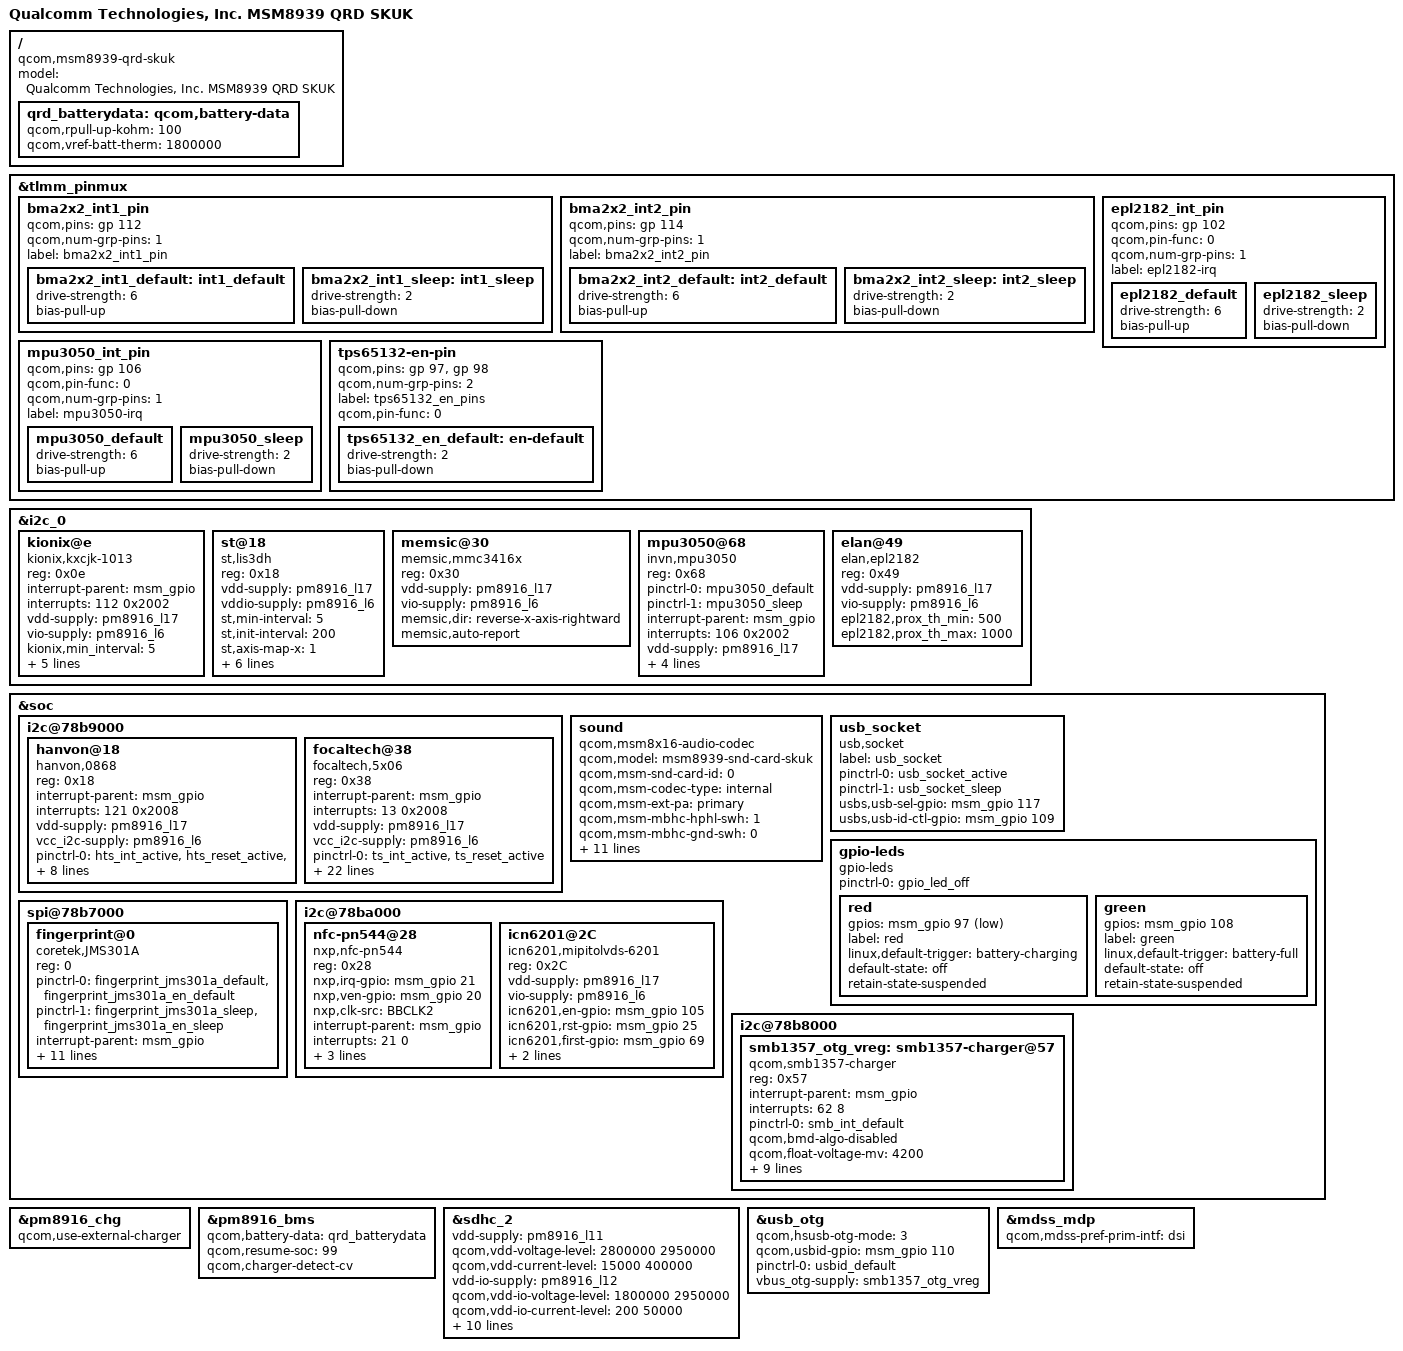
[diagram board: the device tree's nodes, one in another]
/* Copyright (c) 2014, The Linux Foundation. All rights reserved.
 *
 * This program is free software; you can redistribute it and/or modify
 * it under the terms of the GNU General Public License version 2 and
 * only version 2 as published by the Free Software Foundation.
 *
 * This program is distributed in the hope that it will be useful,
 * but WITHOUT ANY WARRANTY; without even the implied warranty of
 * MERCHANTABILITY or FITNESS FOR A PARTICULAR PURPOSE.  See the
 * GNU General Public License for more details.
 */

#include "msm8939-qrd.dtsi"
//#include "dsi-panel-nt35596-1080p-skuk-video.dtsi"
//#include "dsi-panel-nt51021-1200p-skuk-video.dtsi"		// lee add, 20141224
#include "msm8939-camera-sensor-qrd.dtsi"
#include "msm8916-mdss-panels.dtsi"
/ {
	model = "Qualcomm Technologies, Inc. MSM8939 QRD SKUK";
	compatible = "qcom,msm8939-qrd-skuk", "qcom,msm8939-qrd", "qcom,msm8939", "qcom,qrd";
};

&tlmm_pinmux {
	bma2x2_int1_pin {
		qcom,pins = <&gp 112>;
		qcom,num-grp-pins = <1>;
		label = "bma2x2_int1_pin";
		bma2x2_int1_default: int1_default {
			  drive-strength = <6>;
			  bias-pull-up;
		};
		bma2x2_int1_sleep: int1_sleep {
			  drive-strength = <2>;
			  bias-pull-down;
		};
	};

	bma2x2_int2_pin {
		qcom,pins = <&gp 114>;
		qcom,num-grp-pins = <1>;
		label = "bma2x2_int2_pin";
		bma2x2_int2_default: int2_default {
			  drive-strength = <6>;
			  bias-pull-up;
		};
		bma2x2_int2_sleep: int2_sleep {
			  drive-strength = <2>;
			  bias-pull-down;
		};
	};

	epl2182_int_pin {
		qcom,pins = <&gp 102>;
		qcom,pin-func = <0>;
		qcom,num-grp-pins = <1>;
		label = "epl2182-irq";
		epl2182_default: epl2182_default {
			drive-strength = <6>;
			bias-pull-up;
		};
		epl2182_sleep: epl2182_sleep {
			drive-strength = <2>;
			bias-pull-down;
		};
	};

	mpu3050_int_pin {
		qcom,pins = <&gp 106>;
		qcom,pin-func = <0>;
		qcom,num-grp-pins = <1>;
		label = "mpu3050-irq";
		mpu3050_default: mpu3050_default {
			drive-strength = <6>;
			bias-pull-up;
		};
		mpu3050_sleep: mpu3050_sleep {
			drive-strength = <2>;
			bias-pull-down;
		};
	};
	
/*	hall_int_pin {
		qcom,pins = <&gp 121>;
		qcom,pin-func = <0>;
		qcom,num-grp-pins = <1>;
		label = "hall-irq";
		hall_default: hall_default {
			drive-strength = <6>;
			bias-disable;
		};
		hall_sleep: hall_sleep {
			drive-strength = <2>;
			bias-disable;
		};
	};*/
	
	tps65132-en-pin {
		qcom,pins = <&gp 97>, <&gp 98>;
		qcom,num-grp-pins = <2>;
		label = "tps65132_en_pins";
		qcom,pin-func = <0>;

		tps65132_en_default: en-default {
			drive-strength = <2>;
			bias-pull-down;
		};
	};
};

&i2c_0 { /* BLSP1 QUP2 */
/*	avago@96 { // Ambient light and proximity sensor
		compatible = "avago,apds9930";
		reg = <0x96>;
		pinctrl-names = "default","sleep";
		pinctrl-0 = <&apds99xx_default>;
		pinctrl-1 = <&apds99xx_sleep>;
		interrupt-parent = <&msm_gpio>;
		interrupts = <113 0x2002>;
		vdd-supply = <&pm8916_l17>;
		vio-supply = <&pm8916_l6>;
		avago,irq-gpio = <&msm_gpio 113 0x2002>;
		avago,ps-threshold = <600>;
		avago,ps-hysteresis-threshold = <500>;
		avago,ps-pulse = <8>;
		avago,ps-pgain = <0>;
		avago,als-B = <186>;
		avago,als-C = <75>;
		avago,als-D = <129>;
		avago,ga-value = <560>;
	};
*/
/*
	bosch@18 { // Accelerometer sensor
		compatible = "bosch,bma2x2";
		reg = <0x18>;
		pinctrl-names = "bma_default","bma_sleep";
		pinctrl-0 = <&bma2x2_int1_default &bma2x2_int2_default>;
		pinctrl-1 = <&bma2x2_int1_sleep &bma2x2_int2_sleep>;
		interrupt-parent = <&msm_gpio>;
		interrupts = <112 0x2002>;
		vdd-supply = <&pm8916_l17>;
		vio-supply = <&pm8916_l6>;
		bosch,init-interval = <200>;
		bosch,place = <2>;
		bosch,gpio-int1 = <&msm_gpio 112 0x2002>;
		bosch,gpio-int2 = <&msm_gpio 114 0x2002>;
	};
*/
	// lee add, 20150105, for G-sensor.
	kionix@e { /* Accelerometer sensor */
		compatible = "kionix,kxcjk-1013";
		reg = <0x0e>;
		interrupt-parent = <&msm_gpio>;
		interrupts = <112 0x2002>;
		vdd-supply = <&pm8916_l17>;
		vio-supply = <&pm8916_l6>;
		kionix,min_interval = <5>;
		kionix,poll_interval = <100>;
		kionix,accel_direction = <8>;
		kionix,accel_irq_use_drdy = <0>;
		kionix,accel_res = <12>;
		kionix,accel_g_range = <2>;
	};
	// lee add, 20150130, for G-sensor.
	st@18 {
		compatible = "st,lis3dh";
		reg = <0x18>;
		vdd-supply = <&pm8916_l17>;
		vddio-supply = <&pm8916_l6>;
		st,min-interval = <5>;
		st,init-interval = <200>;
		st,axis-map-x = <1>;
		st,axis-map-y = <0>;
		st,axis-map-z = <2>;
		st,g-range = <2>;
		st,gpio-int1 = <&msm_gpio 112 0x2002>;
		st,negate-x;
//		st,negate-y;
		st,negate-z;
	};

	memsic@30 { /* Magnetic field sensor */
		compatible = "memsic,mmc3416x";
		reg = <0x30>;
		vdd-supply = <&pm8916_l17>;
		vio-supply = <&pm8916_l6>;
		memsic,dir = "reverse-x-axis-rightward";
//		memsic,dir = "obverse-x-axis-leftward";
		memsic,auto-report;
	};

	// lee add, 20150105, for Gyroscope sensor.
	mpu3050@68 {
		#address-cells = <1>;
		#size-cells = <0>;
		status = "okay";
		reg = <0x68>;
		compatible = "invn,mpu3050";
		pinctrl-names = "default","sleep";
		pinctrl-0 = <&mpu3050_default>;
		pinctrl-1 = <&mpu3050_sleep>;
		interrupt-parent = <&msm_gpio>;
		interrupts = <106 0x2002>;
		vdd-supply = <&pm8916_l17>;
		vlogic-supply = <&pm8916_l6>;
		invn,gpio-int = <&msm_gpio 106 0x2002>;
		invn,gpio-en = <&pm8916_gpios 3 0x2>;
		invn,poll-interval = <200>;
	};
	
	// lee add, 20150105, for Ambient light and proximity sensor.
	elan@49 { // Ambient light and proximity sensor
		compatible = "elan,epl2182";
		reg = <0x49>;
//		pinctrl-names = "default","sleep";
//		pinctrl-0 = <&epl2182_default>;
//		pinctrl-1 = <&epl2182_sleep>;
//		interrupt-parent = <&msm_gpio>;
//		interrupts = <113 0x2002>;
		vdd-supply = <&pm8916_l17>;
		vio-supply = <&pm8916_l6>;
//		epl2182,irq-gpio = <&msm_gpio 113 0x2002>;
		epl2182,prox_th_min = <500>;
		epl2182,prox_th_max = <1000>;
	};

/*
	mpu6050@68 { // Gyroscope and accelerometer sensor combo
		compatible = "invn,mpu6050";
		reg = <0x68>;
		pinctrl-names = "mpu_default","mpu_sleep";
		pinctrl-0 = <&mpu6050_default>;
		pinctrl-1 = <&mpu6050_sleep>;
		interrupt-parent = <&msm_gpio>;
		interrupts = <106 0x2002>;
		vdd-supply = <&pm8916_l17>;
		vlogic-supply = <&pm8916_l16>;
		vi2c-supply = <&pm8916_l6>;
		invn,gpio-int = <&msm_gpio 106 0x2002>;
		invn,place = "Portrait Down Back Side";
	};
*/
/*
	tps65132@3e {
		compatible = "ti,tps65132";
		reg = <0x3e>;
		i2c-pwr-supply = <&pm8916_l6>;
		ti,en-gpio-lpm;
		pinctrl-names = "default";
		pinctrl-0 = <&tps65132_en_default>;

		regulators {
			tps65132_pos: pos-boost {
				regulator-name = "tps65132-pos";
				regulator-min-microvolt = <5800000>;
				regulator-max-microvolt = <5800000>;
				ti,discharge-enable;
				ti,enable-time = <800>;
				ti,current-limit = <200000>;
				ti,en-gpio = <&msm_gpio 97 0>;
			};

			tps65132_neg: neg-boost {
				regulator-name = "tps65132-neg";
				regulator-min-microvolt = <5800000>;
				regulator-max-microvolt = <5800000>;
				ti,discharge-enable;
				ti,enable-time = <800>;
				ti,current-limit = <40000>;
				ti,en-gpio = <&msm_gpio 98 0>;
			};
		};
	};
*/
};

&soc {
	i2c@78b9000 { /* BLSP1 QUP5 */
	    hanvon@18 {
			compatible = "hanvon,0868";
			reg = <0x18>;
			interrupt-parent = <&msm_gpio>;
			interrupts = <121 0x2008>;
			vdd-supply = <&pm8916_l17>;
			vcc_i2c-supply = <&pm8916_l6>;
			
			pinctrl-names = "pmx_hts_active","pmx_hts_suspend","pmx_hts_release";
			pinctrl-0 = <&hts_int_active &hts_reset_active &hts_sleep_active>;
			pinctrl-1 = <&hts_int_suspend &hts_reset_suspend &hts_sleep_suspend>;
			pinctrl-2 = <&hts_release>;
			
			hanvon,vdd-gpio = <&msm_gpio 88 0x0>;
			hanvon,irq-gpio = <&msm_gpio 121 0x0>;
			hanvon,reset-gpio = <&msm_gpio 72 0x0>;
			hanvon,sleep-gpio = <&msm_gpio 73 0x0>;
		};
		
		focaltech@38 {
			compatible = "focaltech,5x06";
			reg = <0x38>;
			interrupt-parent = <&msm_gpio>;
			interrupts = <13 0x2008>;
			vdd-supply = <&pm8916_l17>;
			vcc_i2c-supply = <&pm8916_l6>;
			pinctrl-names = "pmx_ts_active","pmx_ts_suspend","pmx_ts_release";
			pinctrl-0 = <&ts_int_active &ts_reset_active>;
			pinctrl-1 = <&ts_int_suspend &ts_reset_suspend>;
			pinctrl-2 = <&ts_release>;
			focaltech,name = "ft5606";
			focaltech,family-id = <0x14>;
			focaltech,reset-gpio = <&msm_gpio 12 0x0>;
			focaltech,irq-gpio = <&msm_gpio 13 0x2008>;
			focaltech,display-coords = <0 0 1280 800>;
			focaltech,panel-coords = <0 0 1280 800>;
			focaltech,no-force-update;
			focaltech,i2c-pull-up;
			focaltech,group-id = <1>;
			focaltech,hard-reset-delay-ms = <20>;
			focaltech,soft-reset-delay-ms = <200>;
			focaltech,num-max-touches = <10>;
			focaltech,fw-delay-aa-ms = <30>;
			focaltech,fw-delay-55-ms = <30>;
			focaltech,fw-upgrade-id1 = <0x11>;
			focaltech,fw-upgrade-id2 = <0x11>;
			focaltech,fw-delay-readid-ms = <10>;
			focaltech,fw-delay-era-flsh-ms = <2000>;
			focaltech,fw-auto-cal;
			focaltech,ignore-id-check;
		};
	};


/*	gen-vkeys {
		compatible = "qcom,gen-vkeys";
		label = "ft5x06_ts";		
		qcom,disp-maxx = <1200>;
		qcom,disp-maxy = <1920>;
		qcom,panel-maxx = <1200>;
		qcom,panel-maxy = <1920>;			// need modify, lee 1225
//		qcom,key-codes = <139 172 158>;
		qcom,y-offset = <0>;
	};		*/
	
	sound {
		compatible = "qcom,msm8x16-audio-codec";
		qcom,model = "msm8939-snd-card-skuk";
		qcom,msm-snd-card-id = <0>;
		qcom,msm-codec-type = "internal";
		qcom,msm-ext-pa = "primary";
		qcom,msm-mbhc-hphl-swh = <1>;
		qcom,msm-mbhc-gnd-swh = <0>;
		qcom,msm-micbias1-ext-cap;
		qcom,msm-hs-micbias-type = "internal";
		qcom,audio-routing =
			"RX_BIAS", "MCLK",
			"SPK_RX_BIAS", "MCLK",
			"INT_LDO_H", "MCLK",
			"MIC BIAS External", "Handset Mic",
			"MIC BIAS Internal2", "Headset Mic",
			"MIC BIAS External", "Secondary Mic",
			"AMIC1", "MIC BIAS External",
			"AMIC2", "MIC BIAS Internal2",
			"AMIC3", "MIC BIAS External";
		pinctrl-names = "cdc_lines_act",
				"cdc_lines_sus";
		pinctrl-0 = <&cdc_pdm_lines_act>;
		pinctrl-1 = <&cdc_pdm_lines_sus>;
	};
	// lee add, 20150107 for hall dirver.
/*	hall {
		compatible = "rohs,bu5002";
		label = "hall";
		pinctrl-names = "default","sleep";
		pinctrl-0 = <&hall_default>;
		pinctrl-1 = <&hall_sleep>;
		interrupt-parent = <&msm_gpio>;
		interrupts = <121 0x2002>;
		vio-supply = <&pm8916_l6>;
		hall,irq-gpio = <&msm_gpio 121 0x2002>;
	};
	switch-gpio {
		compatible = "qcom,switch-gpio";
		input-name = "switch-gpio";
		switch,gpio_name="hall";
		switch,gpio = <&msm_gpio 121 0x1>;
		switch,name_on="hall_name_on";
		switch,name_off="hall_name_off";
		switch,state_on="1";
		switch,state_off="0";
			
	};*/

	// for usb socket dirver.
	usb_socket {
		compatible = "usb,socket";
		label = "usb_socket";
		pinctrl-names = "default","sleep";
		pinctrl-0 = <&usb_socket_active>;
		pinctrl-1 = <&usb_socket_sleep>;
		usbs,usb-sel-gpio = <&msm_gpio 117 0x2002>;
		usbs,usb-id-ctl-gpio = <&msm_gpio 109 0x2002>;
	};

	// lee add, 20150108
	gpio-leds {
		compatible = "gpio-leds";
		status = "okay";
		pinctrl-names = "default";
		pinctrl-0 = <&gpio_led_off>;

		red {
			gpios = <&msm_gpio 97 1>;
			label = "red";
			linux,default-trigger = "battery-charging";
			default-state = "off";	// on: led red off, off: led on.
			retain-state-suspended;
		};

		green {
			gpios = <&msm_gpio 108 0>;
			label = "green";
			linux,default-trigger = "battery-full";
			default-state = "off";	// on: led green on, off: led off.
			retain-state-suspended;
		};

	};
	
	// lee add, 20150109
	spi@78b7000 {
		fingerprint@0 {
			compatible = "coretek,JMS301A";
			reg = <0>;
			pinctrl-names = "default","sleep";
			pinctrl-0 = <&fingerprint_jms301a_default &fingerprint_jms301a_en_default>;
			pinctrl-1 = <&fingerprint_jms301a_sleep &fingerprint_jms301a_en_sleep>;
			interrupt-parent = <&msm_gpio>;
			interrupts = <52 0x2002>;
			spi-max-frequency = <9600000>;
			spi-cpol = <1>;
			spi-cpha = <1>;
			vio-supply = <&pm8916_l6>;
//			vdd-io-supply = <&spi_eth_vreg>;
//			vdd-phy-supply = <&spi_eth_vreg>;
			fingerprint,rst-gpio = <&msm_gpio 49 0x2002>;
			fingerprint,shutdown-gpio = <&msm_gpio 50 0x2002>;
			fingerprint,frm_rdy-gpio = <&msm_gpio 51 0x2002>;
			fingerprint,touch-int-gpio = <&msm_gpio 52 0x2002>;
			fingerprint,en-gpio = <&msm_gpio 16 0x2002>;
			fingerprint,cs_gpio  = <&msm_gpio 10 0>;
		};
	};
	
	i2c@78ba000 { /* BLSP1 QUP6 */
		nfc-pn544@28 {
			compatible = "nxp,nfc-pn544";
			reg = <0x28>;
			nxp,irq-gpio = <&msm_gpio 21 0x00>;
			nxp,ven-gpio = <&msm_gpio 20 0x00>;
			nxp,clk-src = "BBCLK2";
			//nxp,clk-en-gpio = <&msm_gpio 0 0x00>;
			interrupt-parent = <&msm_gpio>;
			interrupts = <21 0>;
			interrupt-names = "nfc_irq";
			//pinctrl-names = "nfc_active","nfc_suspend";
			//pinctrl-0 = <&nfc_int_active &nfc_disable_active>;
			//pinctrl-1 = <&nfc_int_suspend &nfc_disable_suspend>;
			nxp,clkreq-gpio = <&pm8916_gpios 2 0>;
			clocks = <&clock_rpm clk_bb_clk2_pin>;		// <&clock_rpm clk_bb_clk2_a>
			clock-names = "ref_clk";	// bbclk2
			nxp,firm-gpio = <&msm_gpio 98 0x00>;
		};

		icn6201@2C { // icn6201 mipitolvds
			compatible = "icn6201,mipitolvds-6201";
			reg = <0x2C>;
			vdd-supply = <&pm8916_l17>;
			vio-supply = <&pm8916_l6>;
			icn6201,en-gpio = <&msm_gpio 105 0x00>;
			icn6201,rst-gpio = <&msm_gpio 25 0x00>;
			icn6201,first-gpio = <&msm_gpio 69 0x00>;
			icn6201,lcd5v-gpio = <&msm_gpio 92 0x00>;
			icn6201,lcdpwm-gpio = <&msm_gpio 81 0x00>;
		};

/*		nfc-nci@e {
			compatible = "qcom,nfc-nci";
			reg = <0x0e>;
			qcom,irq-gpio = <&msm_gpio 21 0x00>;
			qcom,dis-gpio = <&msm_gpio 20 0x00>;
			qcom,clk-src = "BBCLK2";
			qcom,clk-en-gpio = <&msm_gpio 0 0x00>;
			interrupt-parent = <&msm_gpio>;
			interrupts = <21 0>;
			interrupt-names = "nfc_irq";
			pinctrl-names = "nfc_active","nfc_suspend";
			pinctrl-0 = <&nfc_int_active &nfc_disable_active>;
			pinctrl-1 = <&nfc_int_suspend &nfc_disable_suspend>;
			qcom,clk-gpio = <&pm8916_gpios 2 0>;
			clocks = <&clock_rpm clk_bb_clk2_pin>;
			clock-names = "ref_clk";
		};*/
	};
};

&soc {
	i2c@78b8000 { /* BLSP1 QUP4 */
		smb1357_otg_vreg: smb1357-charger@57 {
			compatible = "qcom,smb1357-charger";
			reg = <0x57>;//base you smb1357 part number, 0x1c or 0x57
			interrupt-parent = <&msm_gpio>;
			interrupts = <62 8>;
			pinctrl-names = "default";
			pinctrl-0 = <&smb_int_default>;

			qcom,bmd-algo-disabled;
			qcom,float-voltage-mv = <4200>;//base so your battery specification 4200 or 4350
			qcom,charging-timeout = <1536>;
			qcom,recharge-thresh-mv = <100>;
			regulator-name = "smb1357_otg_vreg";
			qcom,soft-vfloat-comp-disabled;
			qcom,thermal-mitigation = <1500 700 600 0>;

			qcom,bms-psy-name = "bms";
			qcom,iterm-disabled;
			qcom,inhibit-disabled;
			qcom,bms-controlled-charging;
		};
	};
};

&pm8916_chg {
	status = "okay";
	qcom,use-external-charger; 
};

/ {
	qrd_batterydata: qcom,battery-data {
	qcom,rpull-up-kohm = <100>;
	qcom,vref-batt-therm = <1800000>;

	#include "batterydata-qrd-chooser.dtsi"
	};
};

&pm8916_bms {
	status = "okay";
	qcom,battery-data = <&qrd_batterydata>;
	qcom,resume-soc = <99>;
	qcom,charger-detect-cv;
};

&sdhc_2 {
	vdd-supply = <&pm8916_l11>;
	qcom,vdd-voltage-level = <2800000 2950000>;
	qcom,vdd-current-level = <15000 400000>;

	vdd-io-supply = <&pm8916_l12>;
	qcom,vdd-io-voltage-level = <1800000 2950000>;
	qcom,vdd-io-current-level = <200 50000>;

	pinctrl-names = "active", "sleep";
	pinctrl-0 = <&sdc2_clk_on &sdc2_cmd_on &sdc2_data_on &sdc2_cd_on>;
	pinctrl-1 = <&sdc2_clk_off &sdc2_cmd_off &sdc2_data_off &sdc2_cd_off>;

	#address-cells = <0>;
	interrupt-parent = <&sdhc_2>;
	interrupts = <0 1 2>;
	#interrupt-cells = <1>;
	interrupt-map-mask = <0xffffffff>;
	interrupt-map = <0 &intc 0 125 0
			1 &intc 0 221 0
			2 &msm_gpio 38 0>;
	interrupt-names = "hc_irq", "pwr_irq", "status_irq";
	cd-gpios = <&msm_gpio 38 0x1>;

	status = "ok";
};

&usb_otg {
       qcom,hsusb-otg-mode = <3>;
       qcom,usbid-gpio = <&msm_gpio 110 0>;
       pinctrl-names = "default";
       pinctrl-0 = <&usbid_default>;
       vbus_otg-supply = <&smb1357_otg_vreg>;
};

&mdss_mdp {
	qcom,mdss-pref-prim-intf = "dsi";
};
/*
&pmx_mdss {
	qcom,num-grp-pins = <4>;
	qcom,pins = <&gp 116>, <&gp 17>, <&gp 25>, <&gp 119>;
};

&mdss_dsi0 {
	qcom,dsi-pref-prim-pan = <&dsi_nt51021_1200p_skuk_video>;
	pinctrl-names = "mdss_default", "mdss_sleep";
	pinctrl-0 = <&mdss_dsi_active>;
	pinctrl-1 = <&mdss_dsi_suspend>;

	qcom,platform-enable-gpio = <&msm_gpio 17 0>;
	qcom,platform-reset-gpio = <&msm_gpio 25 0>;
	qcom,platform-bklight-en-gpio = <&msm_gpio 119 0>;
	qcom,regulator-ldo-mode;
//
	vsp-supply = <&tps65132_pos>;
	vsn-supply = <&tps65132_neg>;

	qcom,ctrl-supply-entries {
		/delete-node/ qcom,ctrl-supply-entry@0;
	};

	qcom,panel-supply-entries {
		/delete-node/qcom,panel-supply-entry@0;

		qcom,panel-supply-entry@2 {
			reg = <2>;
			qcom,supply-name = "vsp";
			qcom,supply-min-voltage = <5800000>;
			qcom,supply-max-voltage = <5800000>;
			qcom,supply-enable-load = <200>;
			qcom,supply-disable-load = <0>;
		};

		qcom,panel-supply-entry@3 {
			reg = <3>;
			qcom,supply-name = "vsn";
			qcom,supply-min-voltage = <5800000>;
			qcom,supply-max-voltage = <5800000>;
			qcom,supply-enable-load = <40>;
			qcom,supply-disable-load = <0>;
		};
	};
//
};

&dsi_nt51021_1200p_skuk_video {
	qcom,cont-splash-enabled;
//	qcom,esd-check-enabled;
//	qcom,mdss-dsi-pan-enable-dynamic-fps;
//	qcom,mdss-dsi-pan-fps-update = "dfps_immediate_porch_mode";
};
*/
